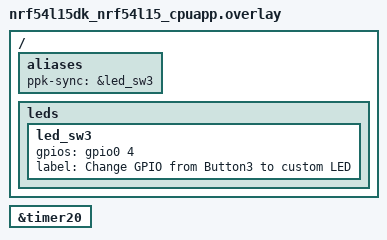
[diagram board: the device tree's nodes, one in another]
/*
 * Copyright (c) 2026 Nordic Semiconductor ASA
 *
 * SPDX-License-Identifier: LicenseRef-Nordic-5-Clause
 */

/* PPK takes cpuapp active/sleep state from P0.04
 * which is Button3 in the board definition.
 * However, Buttons have (GPIO_PULL_UP | GPIO_ACTIVE_LOW).
 * Thus, redefine P0.04 as LED.
 */

/ {
	aliases {
		ppk-sync = &led_sw3;
		/delete-property/ sw3;
	};
};

/delete-node/ &button3;

/ {
	leds {
		led_sw3: led_sw3 {
			gpios = <&gpio0 4 GPIO_ACTIVE_HIGH>;
			label = "Change GPIO from Button3 to custom LED";
		};
	};
};

sample_counter: &timer20 {
	status = "okay";
};
